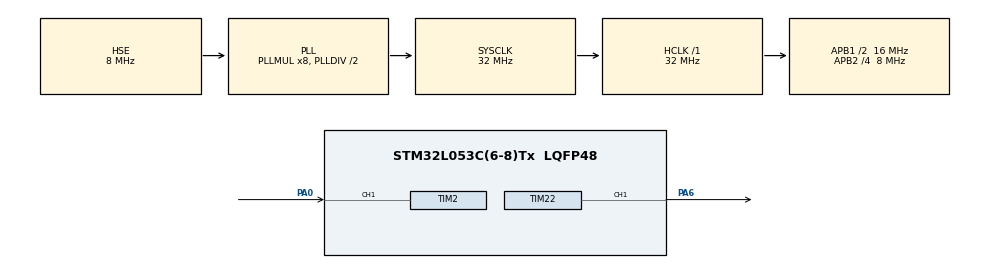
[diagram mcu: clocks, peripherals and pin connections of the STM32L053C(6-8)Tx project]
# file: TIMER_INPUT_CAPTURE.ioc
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Mcu.Family=STM32L0
Mcu.Name=STM32L053C(6-8)Tx
Mcu.Package=LQFP48
NVIC.TIM2_IRQn=true\:0\:0\:false\:false\:true\:true\:true\:true
PA0.Signal=S_TIM2_CH1
PA13.Mode=Serial_Wire
PA13.Signal=SYS_SWDIO
PA14.Mode=Serial_Wire
PA14.Signal=SYS_SWCLK
PA6.Signal=S_TIM22_CH1
PH0-OSC_IN.Mode=HSE-External-Oscillator
PH0-OSC_IN.Signal=RCC_OSC_IN
PH1-OSC_OUT.Mode=HSE-External-Oscillator
PH1-OSC_OUT.Signal=RCC_OSC_OUT
ProjectManager.HeapSize=0x200
ProjectManager.StackSize=0x400
ProjectManager.TargetToolchain=STM32CubeIDE
RCC.AHBFreq_Value=32000000
RCC.APB1CLKDivider=RCC_HCLK_DIV2
RCC.APB1Freq_Value=16000000
RCC.APB1TimFreq_Value=32000000
RCC.APB2CLKDivider=RCC_HCLK_DIV4
RCC.APB2Freq_Value=8000000
RCC.APB2TimFreq_Value=16000000
RCC.HCLKFreq_Value=32000000
RCC.HSE_VALUE=8000000
RCC.HSI16_VALUE=16000000
RCC.HSI48MClockSelection=RCC_USBCLKSOURCE_HSI48
RCC.HSI48_VALUE=48000000
RCC.HSI_VALUE=16000000
RCC.LSE_VALUE=32768
RCC.MSI_VALUE=2097000
RCC.PLLMUL=RCC_PLLMUL_8
RCC.PLLSourceVirtual=RCC_PLLSOURCE_HSE
RCC.RTCClockSelectionVirtual=RCC_RTCCLKSOURCE_LSE
RCC.SYSCLKFreq_VALUE=32000000
RCC.SYSCLKSource=RCC_SYSCLKSOURCE_PLLCLK
RCC.VCOOutputFreq_Value=64000000
SH.S_TIM22_CH1.0=TIM22_CH1,PWM Generation1 CH1
SH.S_TIM2_CH1.0=TIM2_CH1,Input_Capture1_from_TI1
TIM2.Channel-Input_Capture1_from_TI1=TIM_CHANNEL_1
TIM2.Prescaler=16-1
TIM22.Channel-PWM\ Generation1\ CH1=TIM_CHANNEL_1
TIM22.Period=100-1
TIM22.Prescaler=32-1
VP_TIM22_VS_ClockSourceINT.Mode=Internal
VP_TIM2_VS_ClockSourceINT.Mode=Internal
board=STM32L0538-DISCO

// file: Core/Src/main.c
/* USER CODE BEGIN Header */
/**
 ******************************************************************************
 * @file           : main.c
 * @brief          : Main program body
 ******************************************************************************
 * @attention
 *
 * Copyright (c) 2023 STMicroelectronics.
 * All rights reserved.
 *
 * This software is licensed under terms that can be found in the LICENSE file
 * in the root directory of this software component.
 * If no LICENSE file comes with this software, it is provided AS-IS.
 *
 ******************************************************************************
 */
/* USER CODE END Header */
#include "main.h"

TIM_HandleTypeDef htim2;
TIM_HandleTypeDef htim22;

/* USER CODE BEGIN PV */
uint32_t dutyCycle = 0;
/* USER CODE END PV */

void SystemClock_Config(void);
static void MX_GPIO_Init(void);
static void MX_TIM2_Init(void);
static void MX_TIM22_Init(void);

/* USER CODE BEGIN 0 */

#define TIMCLOCK 16000000
#define PRESCALER 16

uint32_t IC_VAL1 = 0;
uint32_t IC_VAL2 = 0;
uint32_t Difference = 0;
int Is_First_Captured = 0;
float frequency = 0;
/* USER CODE END 0 */

int main(void) {

	/* MCU Configuration--------------------------------------------------------*/

	/* Reset of all peripherals, Initializes the Flash interface and the Systick. */
	HAL_Init();

	/* Configure the system clock */
	SystemClock_Config();

	/* Initialize all configured peripherals */
	MX_GPIO_Init();
	MX_TIM2_Init();
	MX_TIM22_Init();
	/* USER CODE BEGIN 2 */

	TIM22->CCR1 = 20;
	HAL_TIM_PWM_Start(&htim22, TIM_CHANNEL_1);

	HAL_TIM_IC_Start_IT(&htim2, TIM_CHANNEL_1);
	/* USER CODE END 2 */

	/* Infinite loop */
	while (1) {

		/* USER CODE BEGIN 3 */
		while (dutyCycle < 100) {
			TIM22->CCR1 = 100;
			dutyCycle += 1;
			HAL_Delay(10);
		}
		while (dutyCycle != 0) {
			TIM22->CCR1 =dutyCycle;
			dutyCycle -= 1;
			HAL_Delay(10);
		}
		HAL_Delay(1000);
	}
	/* USER CODE END 3 */
}

void SystemClock_Config(void) {
	RCC_OscInitTypeDef RCC_OscInitStruct = { 0 };
	RCC_ClkInitTypeDef RCC_ClkInitStruct = { 0 };

	/** Configure the main internal regulator output voltage
	 */
	__HAL_PWR_VOLTAGESCALING_CONFIG(PWR_REGULATOR_VOLTAGE_SCALE1);

	/** Initializes the RCC Oscillators according to the specified parameters
	 * in the RCC_OscInitTypeDef structure.
	 */
	RCC_OscInitStruct.OscillatorType = RCC_OSCILLATORTYPE_HSE;
	RCC_OscInitStruct.HSEState = RCC_HSE_ON;
	RCC_OscInitStruct.PLL.PLLState = RCC_PLL_ON;
	RCC_OscInitStruct.PLL.PLLSource = RCC_PLLSOURCE_HSE;
	RCC_OscInitStruct.PLL.PLLMUL = RCC_PLLMUL_8;
	RCC_OscInitStruct.PLL.PLLDIV = RCC_PLLDIV_2;
	if (HAL_RCC_OscConfig(&RCC_OscInitStruct) != HAL_OK) {
		Error_Handler();
	}

	/** Initializes the CPU, AHB and APB buses clocks
	 */
	RCC_ClkInitStruct.ClockType = RCC_CLOCKTYPE_HCLK | RCC_CLOCKTYPE_SYSCLK
			| RCC_CLOCKTYPE_PCLK1 | RCC_CLOCKTYPE_PCLK2;
	RCC_ClkInitStruct.SYSCLKSource = RCC_SYSCLKSOURCE_PLLCLK;
	RCC_ClkInitStruct.AHBCLKDivider = RCC_SYSCLK_DIV1;
	RCC_ClkInitStruct.APB1CLKDivider = RCC_HCLK_DIV2;
	RCC_ClkInitStruct.APB2CLKDivider = RCC_HCLK_DIV4;

	if (HAL_RCC_ClockConfig(&RCC_ClkInitStruct, FLASH_LATENCY_1) != HAL_OK) {
		Error_Handler();
	}
}

static void MX_TIM2_Init(void) {

	TIM_ClockConfigTypeDef sClockSourceConfig = { 0 };
	TIM_MasterConfigTypeDef sMasterConfig = { 0 };
	TIM_IC_InitTypeDef sConfigIC = { 0 };

	htim2.Instance = TIM2;
	htim2.Init.Prescaler = 16 - 1;
	htim2.Init.CounterMode = TIM_COUNTERMODE_UP;
	htim2.Init.Period = 65535;
	htim2.Init.ClockDivision = TIM_CLOCKDIVISION_DIV1;
	htim2.Init.AutoReloadPreload = TIM_AUTORELOAD_PRELOAD_DISABLE;
	if (HAL_TIM_Base_Init(&htim2) != HAL_OK) {
		Error_Handler();
	}
	sClockSourceConfig.ClockSource = TIM_CLOCKSOURCE_INTERNAL;
	if (HAL_TIM_ConfigClockSource(&htim2, &sClockSourceConfig) != HAL_OK) {
		Error_Handler();
	}
	if (HAL_TIM_IC_Init(&htim2) != HAL_OK) {
		Error_Handler();
	}
	sMasterConfig.MasterOutputTrigger = TIM_TRGO_RESET;
	sMasterConfig.MasterSlaveMode = TIM_MASTERSLAVEMODE_DISABLE;
	if (HAL_TIMEx_MasterConfigSynchronization(&htim2, &sMasterConfig)
			!= HAL_OK) {
		Error_Handler();
	}
	sConfigIC.ICPolarity = TIM_INPUTCHANNELPOLARITY_RISING;
	sConfigIC.ICSelection = TIM_ICSELECTION_DIRECTTI;
	sConfigIC.ICPrescaler = TIM_ICPSC_DIV1;
	sConfigIC.ICFilter = 0;
	if (HAL_TIM_IC_ConfigChannel(&htim2, &sConfigIC, TIM_CHANNEL_1) != HAL_OK) {
		Error_Handler();
	}

}

static void MX_TIM22_Init(void) {

	TIM_ClockConfigTypeDef sClockSourceConfig = { 0 };
	TIM_MasterConfigTypeDef sMasterConfig = { 0 };
	TIM_OC_InitTypeDef sConfigOC = { 0 };

	htim22.Instance = TIM22;
	htim22.Init.Prescaler = 32 - 1;
	htim22.Init.CounterMode = TIM_COUNTERMODE_UP;
	htim22.Init.Period = 100 - 1;
	htim22.Init.ClockDivision = TIM_CLOCKDIVISION_DIV1;
	htim22.Init.AutoReloadPreload = TIM_AUTORELOAD_PRELOAD_DISABLE;
	if (HAL_TIM_Base_Init(&htim22) != HAL_OK) {
		Error_Handler();
	}
	sClockSourceConfig.ClockSource = TIM_CLOCKSOURCE_INTERNAL;
	if (HAL_TIM_ConfigClockSource(&htim22, &sClockSourceConfig) != HAL_OK) {
		Error_Handler();
	}
	if (HAL_TIM_PWM_Init(&htim22) != HAL_OK) {
		Error_Handler();
	}
	sMasterConfig.MasterOutputTrigger = TIM_TRGO_RESET;
	sMasterConfig.MasterSlaveMode = TIM_MASTERSLAVEMODE_DISABLE;
	if (HAL_TIMEx_MasterConfigSynchronization(&htim22, &sMasterConfig)
			!= HAL_OK) {
		Error_Handler();
	}
	sConfigOC.OCMode = TIM_OCMODE_PWM1;
	sConfigOC.Pulse = 0;
	sConfigOC.OCPolarity = TIM_OCPOLARITY_HIGH;
	sConfigOC.OCFastMode = TIM_OCFAST_DISABLE;
	if (HAL_TIM_PWM_ConfigChannel(&htim22, &sConfigOC, TIM_CHANNEL_1)
			!= HAL_OK) {
		Error_Handler();
	}
	HAL_TIM_MspPostInit(&htim22);

}

static void MX_GPIO_Init(void) {

	/* GPIO Ports Clock Enable */
	__HAL_RCC_GPIOH_CLK_ENABLE();
	__HAL_RCC_GPIOA_CLK_ENABLE();

}

/* USER CODE BEGIN 4 */
/* Measure Frequency */
void HAL_TIM_IC_CaptureCallback(TIM_HandleTypeDef *htim) {
	if (htim->Channel == HAL_TIM_ACTIVE_CHANNEL_1) {
		if (Is_First_Captured == 0) //if the first rising edge is not captured
				{
			IC_VAL1 = HAL_TIM_ReadCapturedValue(htim, TIM_CHANNEL_1); //read the first value
			Is_First_Captured = 1; //set the Is_First_Captured true
		}

		else //if the first rising edge is captured then now we will capture the second rising edge
		{
			IC_VAL2 = HAL_TIM_ReadCapturedValue(htim, TIM_CHANNEL_1); //read the second value
			if (IC_VAL2 > IC_VAL1) {
				Difference = IC_VAL2 - IC_VAL1;
			} else if (IC_VAL1 > IC_VAL2) {
				Difference = (0xffffffff - IC_VAL1) + IC_VAL2;
			}
			float refClock = TIMCLOCK / (PRESCALER);

			frequency = refClock / Difference;

			__HAL_TIM_SET_COUNTER(htim, 0); //reset the counter
			Is_First_Captured = 0; //set it back to false
		}
	}
}
/* USER CODE END 4 */

void Error_Handler(void) {
	__disable_irq();
	while (1) {
	}
}
